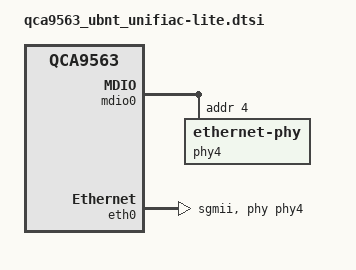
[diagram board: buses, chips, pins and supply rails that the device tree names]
// SPDX-License-Identifier: GPL-2.0-or-later OR MIT

#include "qca9563_ubnt_unifiac.dtsi"

/ {
	aliases {
		label-mac-device = &eth0;
	};
};

&mdio0 {
	status = "okay";

	phy-mask = <4>;
	phy4: ethernet-phy@4 {
		phy-mode = "sgmii";
		reg = <4>;
	};
};

&eth0 {
	status = "okay";

	mtd-mac-address = <&art 0x0>;
	phy-mode = "sgmii";
	phy-handle = <&phy4>;

	pll-data = <0x03000000 0x00000101 0x00001313>;
};
